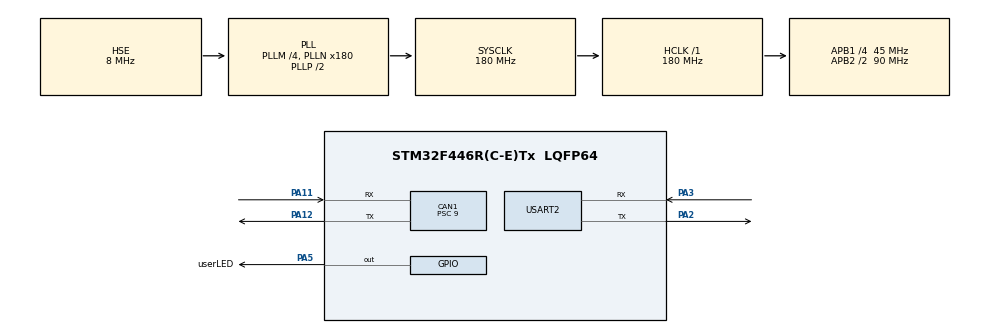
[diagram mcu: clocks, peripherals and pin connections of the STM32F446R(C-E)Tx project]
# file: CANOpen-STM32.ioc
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CAN1.BS1=CAN_BS1_5TQ
CAN1.BS2=CAN_BS2_4TQ
CAN1.CalculateTimeQuantum=200.0
CAN1.Prescaler=9
Dma.Request0=USART2_TX
Dma.Request1=USART2_RX
Dma.USART2_RX.1.Direction=DMA_PERIPH_TO_MEMORY
Dma.USART2_RX.1.FIFOMode=DMA_FIFOMODE_DISABLE
Dma.USART2_RX.1.Instance=DMA1_Stream5
Dma.USART2_RX.1.MemDataAlignment=DMA_MDATAALIGN_BYTE
Dma.USART2_RX.1.MemInc=DMA_MINC_ENABLE
Dma.USART2_RX.1.Mode=DMA_NORMAL
Dma.USART2_RX.1.PeriphDataAlignment=DMA_PDATAALIGN_BYTE
Dma.USART2_RX.1.PeriphInc=DMA_PINC_DISABLE
Dma.USART2_RX.1.Priority=DMA_PRIORITY_LOW
Dma.USART2_TX.0.Direction=DMA_MEMORY_TO_PERIPH
Dma.USART2_TX.0.FIFOMode=DMA_FIFOMODE_DISABLE
Dma.USART2_TX.0.Instance=DMA1_Stream6
Dma.USART2_TX.0.MemDataAlignment=DMA_MDATAALIGN_BYTE
Dma.USART2_TX.0.MemInc=DMA_MINC_ENABLE
Dma.USART2_TX.0.Mode=DMA_NORMAL
Dma.USART2_TX.0.PeriphDataAlignment=DMA_PDATAALIGN_BYTE
Dma.USART2_TX.0.PeriphInc=DMA_PINC_DISABLE
Dma.USART2_TX.0.Priority=DMA_PRIORITY_LOW
FREERTOS.Tasks01=defaultTask,24,128,StartDefaultTask,Default,NULL,Static,defaultTaskBuffer,defaultTaskControlBlock;ledTask,8,128,StartLedTask,Default,NULL,Static,ledTaskBuffer,ledTaskControlBlock;uartPrintTask,8,512,StartUartPrintTask,Default,NULL,Static,uartPrintTaskBuffer,uartPrintTaskControlBlock
Mcu.Family=STM32F4
Mcu.Name=STM32F446R(C-E)Tx
Mcu.Package=LQFP64
NVIC.CAN1_RX0_IRQn=true\:5\:0\:false\:false\:true\:true\:true\:true
NVIC.CAN1_RX1_IRQn=true\:5\:0\:false\:false\:true\:true\:true\:true
NVIC.CAN1_SCE_IRQn=true\:5\:0\:false\:false\:true\:true\:true\:true
NVIC.DMA1_Stream5_IRQn=true\:5\:0\:false\:false\:true\:true\:false\:true
NVIC.DMA1_Stream6_IRQn=true\:5\:0\:false\:false\:true\:true\:false\:true
NVIC.PriorityGroup=NVIC_PRIORITYGROUP_4
NVIC.TIM1_UP_TIM10_IRQn=true\:0\:0\:false\:false\:true\:false\:false\:true
NVIC.TimeBase=TIM1_UP_TIM10_IRQn
NVIC.TimeBaseIP=TIM1
NVIC.USART2_IRQn=true\:5\:0\:false\:false\:true\:true\:true\:true
PA11.Mode=Master
PA11.Signal=CAN1_RX
PA12.Mode=Master
PA12.Signal=CAN1_TX
PA2.Mode=Asynchronous
PA2.Signal=USART2_TX
PA3.Mode=Asynchronous
PA3.Signal=USART2_RX
PA5.GPIO_Label=userLED
PA5.Signal=GPIO_Output
PC14-OSC32_IN.Mode=LSE-External-Oscillator
PC14-OSC32_IN.Signal=RCC_OSC32_IN
PC15-OSC32_OUT.Mode=LSE-External-Oscillator
PC15-OSC32_OUT.Signal=RCC_OSC32_OUT
PH0-OSC_IN.Mode=HSE-External-Oscillator
PH0-OSC_IN.Signal=RCC_OSC_IN
PH1-OSC_OUT.Mode=HSE-External-Oscillator
PH1-OSC_OUT.Signal=RCC_OSC_OUT
ProjectManager.HeapSize=0x200
ProjectManager.StackSize=0x400
ProjectManager.TargetToolchain=Makefile
RCC.AHBFreq_Value=180000000
RCC.APB1CLKDivider=RCC_HCLK_DIV4
RCC.APB1Freq_Value=45000000
RCC.APB1TimFreq_Value=90000000
RCC.APB2CLKDivider=RCC_HCLK_DIV2
RCC.APB2Freq_Value=90000000
RCC.APB2TimFreq_Value=180000000
RCC.CortexFreq_Value=180000000
RCC.HCLKFreq_Value=180000000
RCC.HSE_VALUE=8000000
RCC.PLLM=4
RCC.PLLN=180
RCC.PLLSourceVirtual=RCC_PLLSOURCE_HSE
RCC.SYSCLKFreq_VALUE=180000000
RCC.SYSCLKSource=RCC_SYSCLKSOURCE_PLLCLK
RCC.USBFreq_Value=180000000
RCC.VCOOutputFreq_Value=360000000
USART2.VirtualMode=VM_ASYNC
VP_FREERTOS_VS_CMSIS_V2.Mode=CMSIS_V2
VP_SYS_VS_tim1.Mode=TIM1
board=custom

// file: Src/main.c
/* USER CODE BEGIN Header */
/**
  ******************************************************************************
  * @file           : main.c
  * @brief          : Main program body
  ******************************************************************************
  * @attention
  *
  * <h2><center>&copy; Copyright (c) 2019 STMicroelectronics.
  * All rights reserved.</center></h2>
  *
  * This software component is licensed by ST under Ultimate Liberty license
  * SLA0044, the "License"; You may not use this file except in compliance with
  * the License. You may obtain a copy of the License at:
  *                             www.st.com/SLA0044
  *
  ******************************************************************************
  */
/* USER CODE END Header */

#include "main.h"
#include "cmsis_os.h"
#include "can.h"
#include "dma.h"
#include "usart.h"
#include "gpio.h"

void SystemClock_Config(void);
void MX_FREERTOS_Init(void);

int main(void)
{

  /* MCU Configuration--------------------------------------------------------*/

  /* Reset of all peripherals, Initializes the Flash interface and the Systick. */
  HAL_Init();

  /* Configure the system clock */
  SystemClock_Config();

  /* Initialize all configured peripherals */
  MX_GPIO_Init();
  MX_CAN1_Init();
  MX_USART2_UART_Init();
  MX_DMA_Init();
  /* USER CODE BEGIN 2 */

  User_CAN_Init();

  /* USER CODE END 2 */

  /* Call init function for freertos objects (in freertos.c) */
  MX_FREERTOS_Init();

  /* Start scheduler */
  osKernelStart();

  /* We should never get here as control is now taken by the scheduler */

  /* Infinite loop */
  while (1)
  {

  }
}

void SystemClock_Config(void)
{
  RCC_OscInitTypeDef RCC_OscInitStruct = {0};
  RCC_ClkInitTypeDef RCC_ClkInitStruct = {0};

  /** Configure the main internal regulator output voltage
  */
  __HAL_RCC_PWR_CLK_ENABLE();
  __HAL_PWR_VOLTAGESCALING_CONFIG(PWR_REGULATOR_VOLTAGE_SCALE1);
  /** Initializes the CPU, AHB and APB busses clocks
  */
  RCC_OscInitStruct.OscillatorType = RCC_OSCILLATORTYPE_HSE;
  RCC_OscInitStruct.HSEState = RCC_HSE_ON;
  RCC_OscInitStruct.PLL.PLLState = RCC_PLL_ON;
  RCC_OscInitStruct.PLL.PLLSource = RCC_PLLSOURCE_HSE;
  RCC_OscInitStruct.PLL.PLLM = 4;
  RCC_OscInitStruct.PLL.PLLN = 180;
  RCC_OscInitStruct.PLL.PLLP = RCC_PLLP_DIV2;
  RCC_OscInitStruct.PLL.PLLQ = 2;
  RCC_OscInitStruct.PLL.PLLR = 2;
  if (HAL_RCC_OscConfig(&RCC_OscInitStruct) != HAL_OK)
  {
    Error_Handler();
  }
  /** Activate the Over-Drive mode
  */
  if (HAL_PWREx_EnableOverDrive() != HAL_OK)
  {
    Error_Handler();
  }
  /** Initializes the CPU, AHB and APB busses clocks
  */
  RCC_ClkInitStruct.ClockType = RCC_CLOCKTYPE_HCLK|RCC_CLOCKTYPE_SYSCLK
                              |RCC_CLOCKTYPE_PCLK1|RCC_CLOCKTYPE_PCLK2;
  RCC_ClkInitStruct.SYSCLKSource = RCC_SYSCLKSOURCE_PLLCLK;
  RCC_ClkInitStruct.AHBCLKDivider = RCC_SYSCLK_DIV1;
  RCC_ClkInitStruct.APB1CLKDivider = RCC_HCLK_DIV4;
  RCC_ClkInitStruct.APB2CLKDivider = RCC_HCLK_DIV2;

  if (HAL_RCC_ClockConfig(&RCC_ClkInitStruct, FLASH_LATENCY_5) != HAL_OK)
  {
    Error_Handler();
  }
}

void HAL_TIM_PeriodElapsedCallback(TIM_HandleTypeDef *htim)
{
  if (htim->Instance == TIM1) {
    HAL_IncTick();
  }
}

void Error_Handler(void)
{
}

/************************ (C) COPYRIGHT STMicroelectronics *****END OF FILE****/

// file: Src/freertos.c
/* USER CODE BEGIN Header */
/**
  ******************************************************************************
  * File Name          : freertos.c
  * Description        : Code for freertos applications
  ******************************************************************************
  * @attention
  *
  * <h2><center>&copy; Copyright (c) 2019 STMicroelectronics.
  * All rights reserved.</center></h2>
  *
  * This software component is licensed by ST under Ultimate Liberty license
  * SLA0044, the "License"; You may not use this file except in compliance with
  * the License. You may obtain a copy of the License at:
  *                             www.st.com/SLA0044
  *
  ******************************************************************************
  */
/* USER CODE END Header */

#include "FreeRTOS.h"
#include "task.h"
#include "main.h"
#include "cmsis_os.h"

/* USER CODE BEGIN Includes */
#include "usart.h"
/* USER CODE END Includes */

typedef StaticTask_t osStaticThreadDef_t;
osThreadId_t defaultTaskHandle;
uint32_t defaultTaskBuffer[ 128 ];
osStaticThreadDef_t defaultTaskControlBlock;
osThreadId_t ledTaskHandle;
uint32_t ledTaskBuffer[ 128 ];
osStaticThreadDef_t ledTaskControlBlock;
osThreadId_t uartPrintTaskHandle;
uint32_t uartPrintTaskBuffer[ 512 ];
osStaticThreadDef_t uartPrintTaskControlBlock;

void StartDefaultTask(void *argument);
void StartLedTask(void *argument);
void StartUartPrintTask(void *argument);

void MX_FREERTOS_Init(void); /* (MISRA C 2004 rule 8.1) */

void MX_FREERTOS_Init(void) {
osKernelInitialize();

  /* Create the thread(s) */
  /* definition and creation of defaultTask */
  const osThreadAttr_t defaultTask_attributes = {
    .name = "defaultTask",
    .stack_mem = &defaultTaskBuffer[0],
    .stack_size = sizeof(defaultTaskBuffer),
    .cb_mem = &defaultTaskControlBlock,
    .cb_size = sizeof(defaultTaskControlBlock),
    .priority = (osPriority_t) osPriorityNormal,
  };
  defaultTaskHandle = osThreadNew(StartDefaultTask, NULL, &defaultTask_attributes);

  /* definition and creation of ledTask */
  const osThreadAttr_t ledTask_attributes = {
    .name = "ledTask",
    .stack_mem = &ledTaskBuffer[0],
    .stack_size = sizeof(ledTaskBuffer),
    .cb_mem = &ledTaskControlBlock,
    .cb_size = sizeof(ledTaskControlBlock),
    .priority = (osPriority_t) osPriorityLow,
  };
  ledTaskHandle = osThreadNew(StartLedTask, NULL, &ledTask_attributes);

  /* definition and creation of uartPrintTask */
  const osThreadAttr_t uartPrintTask_attributes = {
    .name = "uartPrintTask",
    .stack_mem = &uartPrintTaskBuffer[0],
    .stack_size = sizeof(uartPrintTaskBuffer),
    .cb_mem = &uartPrintTaskControlBlock,
    .cb_size = sizeof(uartPrintTaskControlBlock),
    .priority = (osPriority_t) osPriorityLow,
  };
  uartPrintTaskHandle = osThreadNew(StartUartPrintTask, NULL, &uartPrintTask_attributes);

}

void StartDefaultTask(void *argument)
{
  for(;;)
  {
    osDelay(1);
  }
}

void StartLedTask(void *argument)
{
  /* USER CODE BEGIN StartLedTask */
  /* Infinite loop */
  for(;;)
  {
    osDelay(500);
    HAL_GPIO_TogglePin(userLED_GPIO_Port, userLED_Pin);
    UART_Printf("Toggle LED Pin.\r\n");

  }
  /* USER CODE END StartLedTask */
}

void StartUartPrintTask(void *argument)
{
  for(;;)
  {
    osDelay(1);
  }
}

/************************ (C) COPYRIGHT STMicroelectronics *****END OF FILE****/
